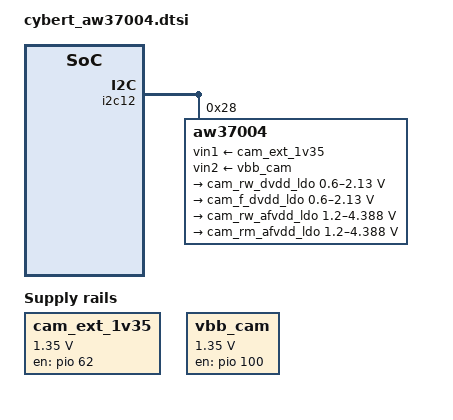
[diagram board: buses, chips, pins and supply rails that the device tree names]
&odm{
    cam_ext_1v35: gpio62-fixed {
        compatible = "regulator-fixed";
        regulator-name = "vcam_ext_gpio_regulator";
        regulator-min-microvolt = <1350000>;
        regulator-max-microvolt = <1350000>;
        enable-active-high;
        regulator-always-on;
        regulator-boot-on;
        gpio = <&pio 62 0x0>;
    };

    vbb_cam: gpio100-fixed {
        compatible = "regulator-fixed";
        regulator-name = "vbb_cam_en_regulator";
        regulator-min-microvolt = <1350000>;
        regulator-max-microvolt = <1350000>;
        enable-active-high;
        regulator-always-on;
        regulator-boot-on;
        gpio = <&pio 100 0x0>;
    };
};

&i2c12{
    aw37004: aw37004@28 {
        status = "okay";
        compatible = "aw37004";
        reg = <0x28>;
        vin1-supply = <&cam_ext_1v35>;
        vin2-supply = <&vbb_cam>;
        init-value = <0x00>;
        regulators{
            cam_rw_dvdd_ldo: ldo1 {
                regulator-name = "aw37004_ldo1";
                regulator-min-microvolt = <600000>;
                regulator-max-microvolt = <2130000>;
            };

            cam_f_dvdd_ldo: ldo2 {
                regulator-name = "aw37004_ldo2";
                regulator-min-microvolt = <600000>;
                regulator-max-microvolt = <2130000>;

            };

            cam_rw_afvdd_ldo: ldo3 {
                regulator-name = "aw37004_ldo3";
                regulator-min-microvolt = <1200000>;
                regulator-max-microvolt = <4387500>;

            };

            cam_rm_afvdd_ldo: ldo4 {
                regulator-name = "aw37004_ldo4";
                regulator-min-microvolt = <1200000>;
                regulator-max-microvolt = <4387500>;

            };
        };
    };
};
